# f29h85x_memss_m_config_regs register map
Vendor: Texas Instruments
Peripheral module from a debugger description file (folder HSM).
Registers are 32-bit, read-write, no defined reset value unless marked. A register's access mark holds for its fields unless they carry their own. Offsets are as the file gives them; lines under a group give offsets from that group; [hi:lo] are bit positions; {n}, {i} and the like mark numbered series; 'fields as' and 'values as' point back to an identical list; <NAME> marks a mode.

## MEMSS_M_CONFIG_REGS — MEMSS M CONFIG Registers
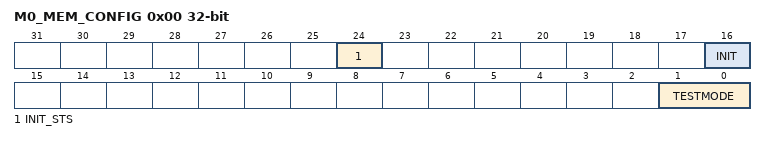
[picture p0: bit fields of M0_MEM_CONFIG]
0x00 M0_MEM_CONFIG access per field — M0 Memory Configuration Register
  [24] INIT_STS ro — M0 INIT status
  [16] INIT rw — Triggers memory Initilization
  [1:0] TESTMODE rw — M0 Test Mode
0x04 M0_MEM_CONFIG_LOCK — Temporary Lock for M0 Memory Configuration Register
  [0] M0_MEM_CONFIG — Temporary Lock
0x08 M0_MEM_CONFIG_COMMIT — Permament Lock for M0 Memory Configuration Register
  [0] M0_MEM_CONFIG_LOCK — Permanent Commit
